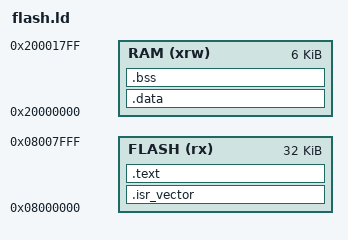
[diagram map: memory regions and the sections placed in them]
ENTRY(Reset_Handler)

MEMORY
{
    FLASH (rx)  : ORIGIN = 0x08000000, LENGTH = 32K
    RAM (xrw)   : ORIGIN = 0x20000000, LENGTH = 6K
}

_estack = ORIGIN(RAM) + LENGTH(RAM);

SECTIONS
{
    .isr_vector :
    {
        . = ALIGN(4);
        KEEP(*(.isr_vector))
        . = ALIGN(4);
    } >FLASH

    .text :
    {
        . = ALIGN(4);
        *(.text)
        *(.text*)
        *(.rodata)
        *(.rodata*)
        . = ALIGN(4);
    } >FLASH

    _sidata = .;
    .data : AT( _sidata )
    {
        . = ALIGN(4);
        _sdata = .;
        *(.data)
        *(.data*)
        . = ALIGN(4);
        _edata = .;
    } >RAM

    . = ALIGN(4);
    .bss :
    {
        _sbss = .;
        *(.bss)
        *(.bss*)
        *(COMMON)
        . = ALIGN(4);
        _ebss = .;
    } >RAM
}
